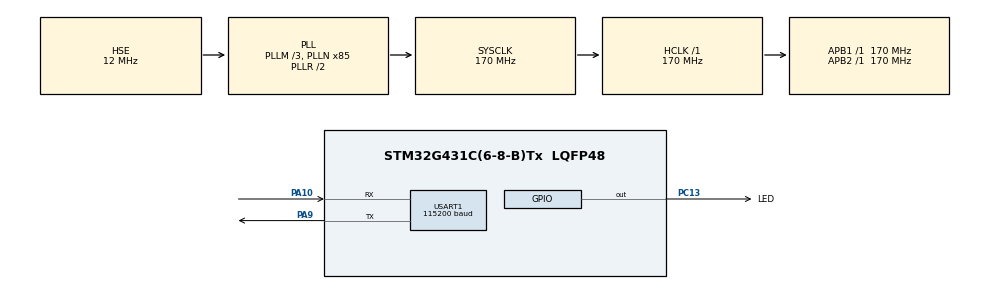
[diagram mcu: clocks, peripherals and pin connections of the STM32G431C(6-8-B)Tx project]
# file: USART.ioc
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Mcu.Family=STM32G4
Mcu.Name=STM32G431C(6-8-B)Tx
Mcu.Package=LQFP48
NVIC.PriorityGroup=NVIC_PRIORITYGROUP_4
NVIC.USART1_IRQn=true\:0\:0\:false\:false\:true\:true\:true\:true
PA10.Mode=Asynchronous
PA10.Signal=USART1_RX
PA9.Mode=Asynchronous
PA9.Signal=USART1_TX
PC13.GPIO_Label=LED
PC13.Signal=GPIO_Output
PF0-OSC_IN.Mode=HSE-External-Oscillator
PF0-OSC_IN.Signal=RCC_OSC_IN
PF1-OSC_OUT.Mode=HSE-External-Oscillator
PF1-OSC_OUT.Signal=RCC_OSC_OUT
ProjectManager.HeapSize=0x200
ProjectManager.StackSize=0x400
ProjectManager.TargetToolchain=MDK-ARM V5.32
RCC.ADC12Freq_Value=170000000
RCC.AHBFreq_Value=170000000
RCC.APB1Freq_Value=170000000
RCC.APB1TimFreq_Value=170000000
RCC.APB2Freq_Value=170000000
RCC.APB2TimFreq_Value=170000000
RCC.CortexFreq_Value=170000000
RCC.EXTERNAL_CLOCK_VALUE=12288000
RCC.FLatency=FLASH_LATENCY_4
RCC.HCLKFreq_Value=170000000
RCC.HSE_VALUE=12000000
RCC.HSI48_VALUE=48000000
RCC.HSI_VALUE=16000000
RCC.LSE_VALUE=32768
RCC.PLLM=RCC_PLLM_DIV3
RCC.PLLN=85
RCC.PLLSourceVirtual=RCC_PLLSOURCE_HSE
RCC.SYSCLKFreq_VALUE=170000000
RCC.SYSCLKSource=RCC_SYSCLKSOURCE_PLLCLK
RCC.USBFreq_Value=170000000
RCC.VCOOutputFreq_Value=340000000
USART1.AutoBaudRateEnableParam=UART_ADVFEATURE_AUTOBAUDRATE_DISABLE
USART1.BaudRate=115200
USART1.ClockPrescaler=PRESCALER_DIV1
USART1.DMADisableonRxErrorParam=ADVFEATURE_DMA_ENABLEONRXERROR
USART1.DataInvertParam=ADVFEATURE_DATAINV_DISABLE
USART1.FIFOMode=FIFOMODE_DISABLE
USART1.MSBFirstParam=ADVFEATURE_MSBFIRST_DISABLE
USART1.Mode=MODE_TX_RX
USART1.OneBitSampling=UART_ONE_BIT_SAMPLE_DISABLE
USART1.OverSampling=UART_OVERSAMPLING_16
USART1.OverrunDisableParam=ADVFEATURE_OVERRUN_ENABLE
USART1.Parity=PARITY_NONE
USART1.RXFIFOThreshold=RXFIFO_THRESHOLD_1EIGHTHFULL
USART1.RxPinLevelInvertParam=ADVFEATURE_RXINV_DISABLE
USART1.StopBits=STOPBITS_1
USART1.SwapParam=ADVFEATURE_SWAP_DISABLE
USART1.TXFIFOThreshold=TXFIFO_THRESHOLD_1EIGHTHFULL
USART1.TxPinLevelInvertParam=ADVFEATURE_TXINV_DISABLE
USART1.VirtualMode-Asynchronous=VM_ASYNC
USART1.WordLength=WORDLENGTH_8B
VP_SYS_VS_DBSignals.Mode=DisableDeadBatterySignals
board=custom

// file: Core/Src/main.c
/* USER CODE BEGIN Header */
/**
  ******************************************************************************
  * @file           : main.c
  * @brief          : Main program body
  ******************************************************************************
  * @attention
  *
  * Copyright (c) 2022 STMicroelectronics.
  * All rights reserved.
  *
  * This software is licensed under terms that can be found in the LICENSE file
  * in the root directory of this software component.
  * If no LICENSE file comes with this software, it is provided AS-IS.
  *
  ******************************************************************************
  */
/* USER CODE END Header */
#include "main.h"
#include "usart.h"
#include "gpio.h"

/* USER CODE BEGIN PV */
uint8_t rx_buf;
uint8_t tx_buf[] = "IO Impulse STM32G431CBTx usart test...\r\n";

/* USER CODE END PV */

void SystemClock_Config(void);

/* USER CODE BEGIN 0 */
void HAL_UART_RxCpltCallback(UART_HandleTypeDef *huart)
{
		if(huart->Instance == USART1) {
				HAL_UART_Transmit(&huart1, &rx_buf, sizeof(rx_buf), 1000);
				HAL_UART_Receive_IT(&huart1, &rx_buf, sizeof(rx_buf));
		}
}

/* USER CODE END 0 */

int main(void)
{

  /* MCU Configuration--------------------------------------------------------*/

  /* Reset of all peripherals, Initializes the Flash interface and the Systick. */
  HAL_Init();

  /* Configure the system clock */
  SystemClock_Config();

  /* Initialize all configured peripherals */
  MX_GPIO_Init();
  MX_USART1_UART_Init();
  /* USER CODE BEGIN 2 */
	/* 开启 USART 1 中断 */
	HAL_UART_Receive_IT(&huart1, &rx_buf, sizeof(rx_buf));

  /* USER CODE END 2 */

  /* Infinite loop */
  /* USER CODE BEGIN WHILE */
  while (1)
  {
		HAL_UART_Transmit(&huart1, tx_buf, sizeof(tx_buf), 1000);
		HAL_Delay(1000);
		HAL_GPIO_TogglePin(LED_GPIO_Port, LED_Pin);
    /* USER CODE END WHILE */

  }
}

void SystemClock_Config(void)
{
  RCC_OscInitTypeDef RCC_OscInitStruct = {0};
  RCC_ClkInitTypeDef RCC_ClkInitStruct = {0};

  /** Configure the main internal regulator output voltage
  */
  HAL_PWREx_ControlVoltageScaling(PWR_REGULATOR_VOLTAGE_SCALE1_BOOST);

  /** Initializes the RCC Oscillators according to the specified parameters
  * in the RCC_OscInitTypeDef structure.
  */
  RCC_OscInitStruct.OscillatorType = RCC_OSCILLATORTYPE_HSE;
  RCC_OscInitStruct.HSEState = RCC_HSE_ON;
  RCC_OscInitStruct.PLL.PLLState = RCC_PLL_ON;
  RCC_OscInitStruct.PLL.PLLSource = RCC_PLLSOURCE_HSE;
  RCC_OscInitStruct.PLL.PLLM = RCC_PLLM_DIV3;
  RCC_OscInitStruct.PLL.PLLN = 85;
  RCC_OscInitStruct.PLL.PLLP = RCC_PLLP_DIV2;
  RCC_OscInitStruct.PLL.PLLQ = RCC_PLLQ_DIV2;
  RCC_OscInitStruct.PLL.PLLR = RCC_PLLR_DIV2;
  if (HAL_RCC_OscConfig(&RCC_OscInitStruct) != HAL_OK)
  {
    Error_Handler();
  }

  /** Initializes the CPU, AHB and APB buses clocks
  */
  RCC_ClkInitStruct.ClockType = RCC_CLOCKTYPE_HCLK|RCC_CLOCKTYPE_SYSCLK
                              |RCC_CLOCKTYPE_PCLK1|RCC_CLOCKTYPE_PCLK2;
  RCC_ClkInitStruct.SYSCLKSource = RCC_SYSCLKSOURCE_PLLCLK;
  RCC_ClkInitStruct.AHBCLKDivider = RCC_SYSCLK_DIV1;
  RCC_ClkInitStruct.APB1CLKDivider = RCC_HCLK_DIV1;
  RCC_ClkInitStruct.APB2CLKDivider = RCC_HCLK_DIV1;

  if (HAL_RCC_ClockConfig(&RCC_ClkInitStruct, FLASH_LATENCY_4) != HAL_OK)
  {
    Error_Handler();
  }
}

void Error_Handler(void)
{
  __disable_irq();
  while (1)
  {
  }
}
